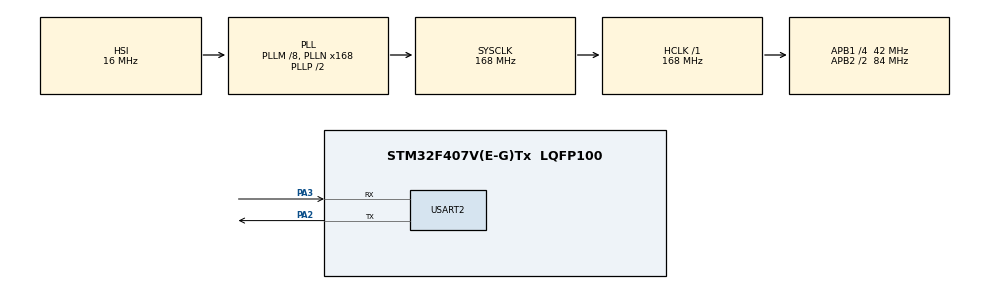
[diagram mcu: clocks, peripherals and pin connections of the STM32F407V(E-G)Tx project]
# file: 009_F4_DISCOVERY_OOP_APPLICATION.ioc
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Mcu.Family=STM32F4
PH0-OSC_IN.Signal=RCC_OSC_IN
RCC.CortexFreq_Value=168000000
RCC.APB1CLKDivider=RCC_HCLK_DIV4
RCC.SYSCLKSource=RCC_SYSCLKSOURCE_PLLCLK
ProjectManager.StackSize=0x400
PA3.Mode=Asynchronous
ProjectManager.TargetToolchain=STM32CubeIDE
RCC.HCLKFreq_Value=168000000
RCC.APB2TimFreq_Value=168000000
RCC.LSE_VALUE=32768
RCC.AHBFreq_Value=168000000
PH0-OSC_IN.Mode=HSE-External-Oscillator
RCC.HSE_VALUE=25000000
board=custom
RCC.VCOOutputFreq_Value=336000000
RCC.APB2Freq_Value=84000000
PH1-OSC_OUT.Signal=RCC_OSC_OUT
Mcu.Name=STM32F407V(E-G)Tx
PA2.Signal=USART2_TX
PH1-OSC_OUT.Mode=HSE-External-Oscillator
RCC.48MHZClocksFreq_Value=84000000
RCC.SYSCLKFreq_VALUE=168000000
Mcu.Package=LQFP100
USART2.VirtualMode=VM_ASYNC
ProjectManager.HeapSize=0x200
RCC.HSI_VALUE=16000000
NVIC.PriorityGroup=NVIC_PRIORITYGROUP_4
RCC.APB2CLKDivider=RCC_HCLK_DIV2
RCC.PLLM=8
RCC.PLLN=168
RCC.APB1TimFreq_Value=84000000
PA2.Mode=Asynchronous
RCC.APB1Freq_Value=42000000
PA3.Signal=USART2_RX

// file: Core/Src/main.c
//* Includes ------------------------------------------------------------------*/
#include "main.h"

/* USER CODE BEGIN Includes */
#include <stdio.h>
#include "retarget.h"
#include "Led.h"
#include "PowerLed.h"
/* USER CODE END Includes */

UART_HandleTypeDef huart2;

/* USER CODE BEGIN PV */
char buf[100];

Led_Type led1, led2, led3, led4;
PowerLed_Type pled1,pled2;
led_elec_type power_led1,power_led2;
/* USER CODE END PV */

void SystemClock_Config(void);
static void MX_GPIO_Init(void);
static void MX_USART2_UART_Init(void);
/* USER CODE BEGIN PFP */
void test_Print_Scanf(void);
/* USER CODE END PFP */

int main(void) {

	/* MCU Configuration--------------------------------------------------------*/

	/* Reset of all peripherals, Initializes the Flash interface and the Systick. */
	HAL_Init();

	/* Configure the system clock */
	SystemClock_Config();

	/* Initialize all configured peripherals */
	MX_GPIO_Init();
	MX_USART2_UART_Init();
	/* USER CODE BEGIN 2 */
	RetargetInit(&huart2);
//** for Led.h test **///
//	Led_ctor(&led1, RED, ON);
//	Led_ctor(&led2, BLUE, ON);
//	Led_ctor(&led3, YELLOW, ON);
//	Led_ctor(&led4, GREEN, ON);
//	Led_getState(&led1);
//	Led_getState(&led2);
//
////  Led_setState(&led, ON);
////  Led_setState(&led2, OFF);

	///** for PowerLed.h test  **//

	PowerLed_ctor(&pled1, BLUE, DIAM_5MM, ON, CURR_NORMAL, VOL_HIGH);
	PowerLed_ctor(&pled2, GREEN, DIAM_7MM, ON, CURR_LOW, CURR_LOW);

	power_led1 = PowerLed_ComputePower(&pled1);
	power_led2 = PowerLed_ComputePower(&pled2);

	/* USER CODE END 2 */

	/* Infinite loop */
	while (1) {

	}
}

// ***REST OF INITIALIZATION CODE NOT SHOWN***
void SystemClock_Config(void) {
	RCC_OscInitTypeDef RCC_OscInitStruct = { 0 };
	RCC_ClkInitTypeDef RCC_ClkInitStruct = { 0 };

	/** Configure the main internal regulator output voltage
	 */
	__HAL_RCC_PWR_CLK_ENABLE();
	__HAL_PWR_VOLTAGESCALING_CONFIG(PWR_REGULATOR_VOLTAGE_SCALE1);
	/** Initializes the RCC Oscillators according to the specified parameters
	 * in the RCC_OscInitTypeDef structure.
	 */
	RCC_OscInitStruct.OscillatorType = RCC_OSCILLATORTYPE_HSI;
	RCC_OscInitStruct.HSIState = RCC_HSI_ON;
	RCC_OscInitStruct.HSICalibrationValue = RCC_HSICALIBRATION_DEFAULT;
	RCC_OscInitStruct.PLL.PLLState = RCC_PLL_ON;
	RCC_OscInitStruct.PLL.PLLSource = RCC_PLLSOURCE_HSI;
	RCC_OscInitStruct.PLL.PLLM = 8;
	RCC_OscInitStruct.PLL.PLLN = 168;
	RCC_OscInitStruct.PLL.PLLP = RCC_PLLP_DIV2;
	RCC_OscInitStruct.PLL.PLLQ = 4;
	if (HAL_RCC_OscConfig(&RCC_OscInitStruct) != HAL_OK) {
		Error_Handler();
	}
	/** Initializes the CPU, AHB and APB buses clocks
	 */
	RCC_ClkInitStruct.ClockType = RCC_CLOCKTYPE_HCLK | RCC_CLOCKTYPE_SYSCLK
			| RCC_CLOCKTYPE_PCLK1 | RCC_CLOCKTYPE_PCLK2;
	RCC_ClkInitStruct.SYSCLKSource = RCC_SYSCLKSOURCE_PLLCLK;
	RCC_ClkInitStruct.AHBCLKDivider = RCC_SYSCLK_DIV1;
	RCC_ClkInitStruct.APB1CLKDivider = RCC_HCLK_DIV4;
	RCC_ClkInitStruct.APB2CLKDivider = RCC_HCLK_DIV2;

	if (HAL_RCC_ClockConfig(&RCC_ClkInitStruct, FLASH_LATENCY_5) != HAL_OK) {
		Error_Handler();
	}
}

static void MX_USART2_UART_Init(void) {

	huart2.Instance = USART2;
	huart2.Init.BaudRate = 115200;
	huart2.Init.WordLength = UART_WORDLENGTH_8B;
	huart2.Init.StopBits = UART_STOPBITS_1;
	huart2.Init.Parity = UART_PARITY_NONE;
	huart2.Init.Mode = UART_MODE_TX_RX;
	huart2.Init.HwFlowCtl = UART_HWCONTROL_NONE;
	huart2.Init.OverSampling = UART_OVERSAMPLING_16;
	if (HAL_UART_Init(&huart2) != HAL_OK) {
		Error_Handler();
	}

}

static void MX_GPIO_Init(void) {

	/* GPIO Ports Clock Enable */
	__HAL_RCC_GPIOH_CLK_ENABLE();
	__HAL_RCC_GPIOA_CLK_ENABLE();

}

/* USER CODE BEGIN 4 */
void test_Print_Scanf(void) {
	printf("\r\nYour name: ");
	scanf("%s", buf);
	printf("\r\nHello, %s!\r\n", buf);
}
/* USER CODE END 4 */

void Error_Handler(void) {
	__disable_irq();
	while (1) {
	}
}

/************************ (C) COPYRIGHT STMicroelectronics *****END OF FILE****/
